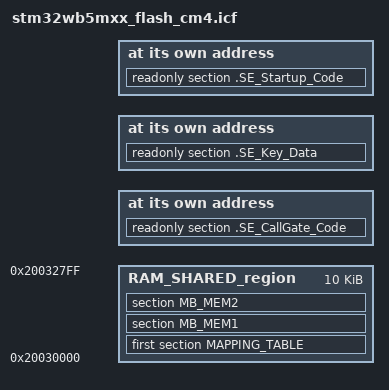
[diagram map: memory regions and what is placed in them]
/*###ICF### Set of symbols used in SE and SB_SFU projects ****/

define memory mem with size = 4G;

/******************************************************************************/
/*       Include of SE symbols file                                           */
/*   (Project>Options>Linker>Extra Options --config_search option is used to  */ 
/*   specify the the directory to search for include files                    */ 
/******************************************************************************/
include "mapping_sbsfu.icf";
include "mapping_fwimg.icf";

initialize by copy { readwrite };
do not initialize  { section .noinit, section MAPPING_TABLE, section MB_MEM1};
define block SE_VECTOR with alignment = 512 {readonly section .intvec };

define symbol __ICFEDIT_region_RAM_SHARED_start__ = 0x20030000;
define symbol __ICFEDIT_region_RAM_SHARED_end__   = 0x200327FF;
define region RAM_SHARED_region = mem:[from __ICFEDIT_region_RAM_SHARED_start__   to __ICFEDIT_region_RAM_SHARED_end__];

/******************************************************************************/
/*                          placement instructions                            */
/******************************************************************************/
place at address mem:__ICFEDIT_SE_CallGate_region_ROM_start__ { readonly section .SE_CallGate_Code };
place at address mem:__ICFEDIT_SE_Key_region_ROM_start__ {readonly section .SE_Key_Data };
place at address mem:__ICFEDIT_SE_Startup_region_ROM_start__ { readonly section .SE_Startup_Code};
place in SE_ROM_region {readonly, block SE_VECTOR};
place in SE_RAM_region {readwrite};
place in RAM_SHARED_region { first section MAPPING_TABLE};
place in RAM_SHARED_region { section MB_MEM1};
place in RAM_SHARED_region { section MB_MEM2};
